VERSION ""

NS_ :

BS_:

BU_:
VAL_TABLE_ motor_sensor 1 "HALL" 0 "Sensorless" ;
VAL_TABLE_ motor_state 5 "FAULT" 4 "RUN" 3 "STOP" 2 "START_DELAY" 1 "ADC_CAL" 0 "INIT" ;

BO_ 3221225472 VECTOR__INDEPENDENT_SIG_MSG: 0 Vector__XXX
 SG_ motor_fault : 0|8@1+ (1,0) [0|0] "" Vector__XXX

BO_ 512 motor_cmd1: 8 Vector__XXX
 SG_ motor_enable : 16|1@1+ (1,0) [0|0] "" Vector__XXX
 SG_ speed_cmd_rpm : 0|16@1+ (1,0) [0|0] "RPM" Vector__XXX

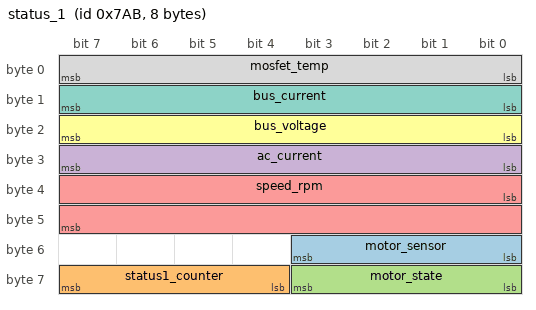
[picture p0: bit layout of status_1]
BO_ 1963 status_1: 8 Vector__XXX
 SG_ motor_sensor : 48|4@1+ (1,0) [0|0] "" Vector__XXX
 SG_ status1_counter : 60|4@1+ (1,0) [0|0] "" Vector__XXX
 SG_ motor_state : 56|4@1+ (1,0) [0|0] "" Vector__XXX
 SG_ ac_current : 24|8@1+ (0.1,0) [0|0] "A" Vector__XXX
 SG_ speed_rpm : 32|16@1+ (1,0) [0|0] "RPM" Vector__XXX
 SG_ bus_voltage : 16|8@1+ (0.166,0) [0|0] "V" Vector__XXX
 SG_ bus_current : 8|8@1+ (0.1,0) [0|0] "A" Vector__XXX
 SG_ mosfet_temp : 0|8@1+ (1,-40) [0|0] "¡æ" Vector__XXX

CM_ BO_ 3221225472 "This is a message for not used signals, created by Vector CANdb++ DBC OLE DB Provider.";
BA_DEF_ SG_  "GenSigSendType" ENUM  "Cyclic","OnWrite","OnWriteWithRepetition","OnChange","OnChangeWithRepetition","IfActive","IfActiveWithRepetition","NoSigSendType";
BA_DEF_ BO_  "GenMsgSendType" ENUM  "Cyclic","not_used","not_used","not_used","not_used","Cyclic","not_used","IfActive","NoMsgSendType";
BA_DEF_  "DBName" STRING ;
BA_DEF_  "BusType" STRING ;
BA_DEF_DEF_  "GenSigSendType" "Cyclic";
BA_DEF_DEF_  "GenMsgSendType" "NoMsgSendType";
BA_DEF_DEF_  "DBName" "";
BA_DEF_DEF_  "BusType" "CAN";
BA_ "DBName" "motor";
VAL_ 1963 motor_sensor 1 "HALL" 0 "Sensorless" ;
VAL_ 1963 motor_state 5 "FAULT" 4 "RUN" 3 "STOP" 2 "START_DELAY" 1 "ADC_CAL" 0 "INIT" ;
